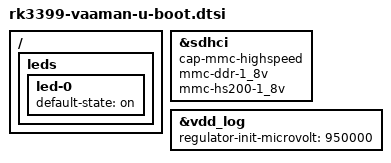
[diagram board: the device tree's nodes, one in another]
// SPDX-License-Identifier: GPL-2.0+
/*
 * Copyright (C) 2026 djkabutar <d.kabutarwala@yahoo.com>
 */

#include "rk3399-u-boot.dtsi"
#include "rk3399-sdram-lpddr4-100.dtsi"

/ {
	leds {
		led-0 {
			default-state = "on";
		};
	};
};

&sdhci {
	cap-mmc-highspeed;
	mmc-ddr-1_8v;
	mmc-hs200-1_8v;
};

&vdd_log {
	regulator-init-microvolt = <950000>;
};
